# M3HM register map
File version: 0.1
Registers are 32-bit, read-write, reset 0x0 unless marked. A register's access mark holds for its fields unless they carry their own. Offsets are from the block's base; [hi:lo] are bit positions; {n}, {i} and the like mark numbered series.

## RPAR — RAM Parity
Base 0x400BBB00
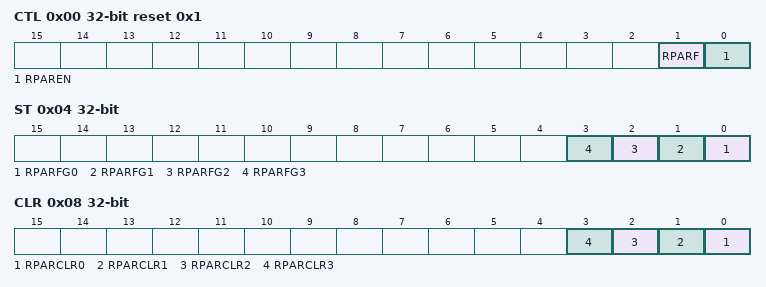
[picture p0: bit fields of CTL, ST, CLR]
0x00 CTL reset 0x1 — RAMM Parity control register
  [1] RPARF, [0] RPAREN
0x04 ST ro — RAMM Parity status register
  [n] RPARFG{n} (n=0..3)
0x08 CLR wo — RAMM Parity status clear register
  [n] RPARCLR{n} (n=0..3)
{0xC+4i} EAD{i} ro (i=0..3) — RAMM Parity Error address register {i}
  [31:0] RPAREADD{i}

## CRC
Base 0x400BBC00
0x00 DIN — CRC input data register
  [31:0] CRCDIN
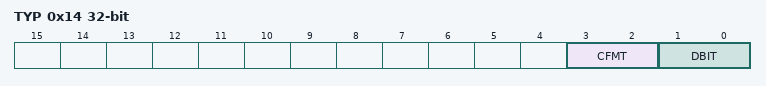
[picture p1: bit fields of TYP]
0x14 TYP — CRC data type register
  [3:2] CFMT, [1:0] DBIT
0x2C CLC reset 0xFFFFFFFF — CRC calculation result register
  [31:0] CRCCLC

## CMP
Base 0x400BC100
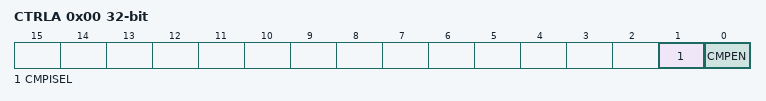
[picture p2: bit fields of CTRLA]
0x00 CTRLA — CMP control register A
  [1] CMPISEL, [0] CMPEN

## PA — Port A
Base 0x400C0000
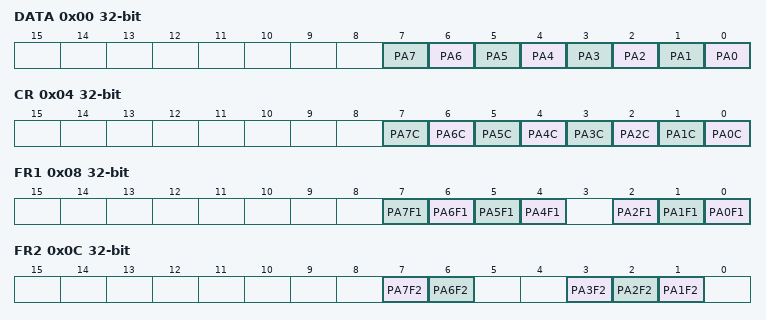
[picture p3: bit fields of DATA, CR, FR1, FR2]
0x00 DATA — PA Data Register
  [n] PA{n} (n=0..7)
0x04 CR — PA Control Register
  [n] PA{n}C (n=0..7)
0x08 FR1 — PA Function Register 1
  [n] PA{n}F1 (n=4..7), [2] PA2F1, [1] PA1F1, [0] PA0F1
0x0C FR2 — PA Function Register 2
  [7] PA7F2, [6] PA6F2, [3] PA3F2, [2] PA2F2, [1] PA1F2
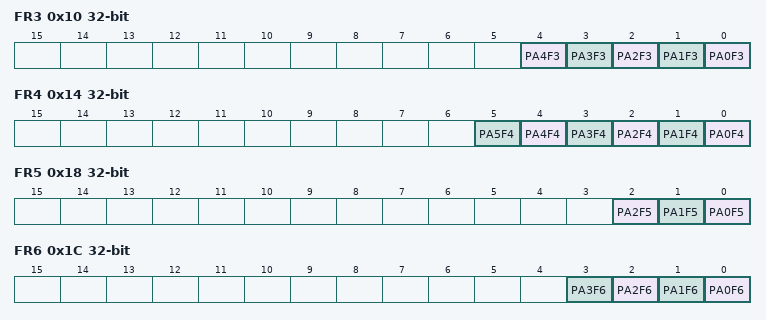
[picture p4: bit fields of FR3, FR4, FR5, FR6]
0x10 FR3 — PA Function Register 3
  [n] PA{n}F3 (n=0..4)
0x14 FR4 — PA Function Register 4
  [n] PA{n}F4 (n=0..5)
0x18 FR5 — PA Function Register 5
  [2] PA2F5, [1] PA1F5, [0] PA0F5
0x1C FR6 — PA Function Register 6
  [n] PA{n}F6 (n=0..3)
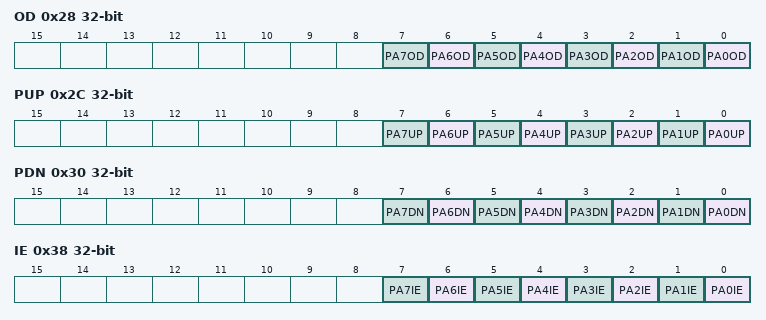
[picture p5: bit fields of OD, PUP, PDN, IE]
0x28 OD — PA Open Drain Control Register
  [n] PA{n}OD (n=0..7)
0x2C PUP — PA Pull-up Control Register
  [n] PA{n}UP (n=0..7)
0x30 PDN — PB Pull-Down Control Register
  [n] PA{n}DN (n=0..7)
0x38 IE — PA Input Enable Control Register
  [n] PA{n}IE (n=0..7)

## PB — Port B
Base 0x400C0100
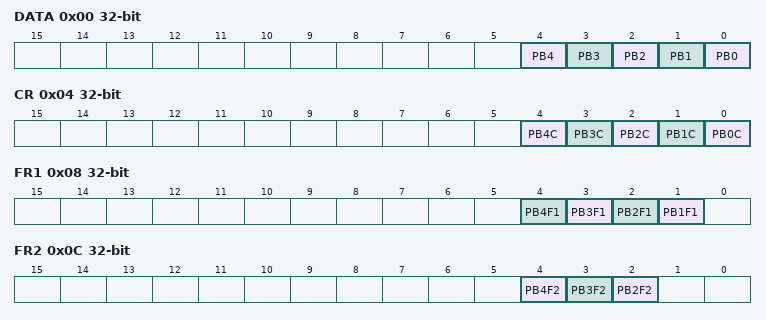
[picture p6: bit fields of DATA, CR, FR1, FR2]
0x00 DATA — PB Data Register
  [n] PB{n} (n=0..4)
0x04 CR — PB Control Register
  [n] PB{n}C (n=0..4)
0x08 FR1 — PB Function Register 1
  [n] PB{n}F1 (n=1..4)
0x0C FR2 — PB Function Register 2
  [4] PB4F2, [3] PB3F2, [2] PB2F2
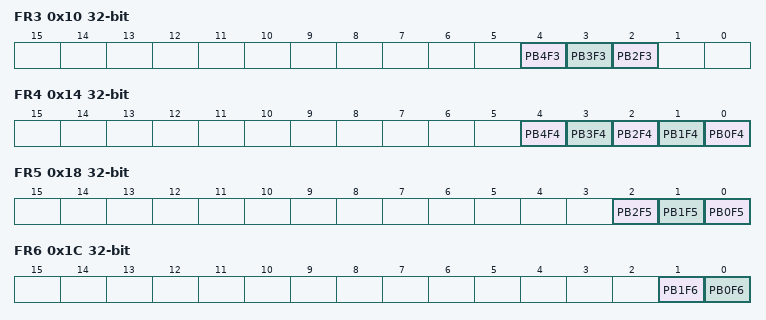
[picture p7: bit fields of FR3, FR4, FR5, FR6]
0x10 FR3 — PB Function Register 3
  [4] PB4F3, [3] PB3F3, [2] PB2F3
0x14 FR4 — PB Function Register 4
  [n] PB{n}F4 (n=0..4)
0x18 FR5 — PB Function Register 5
  [2] PB2F5, [1] PB1F5, [0] PB0F5
0x1C FR6 — PB Function Register 6
  [1] PB1F6, [0] PB0F6
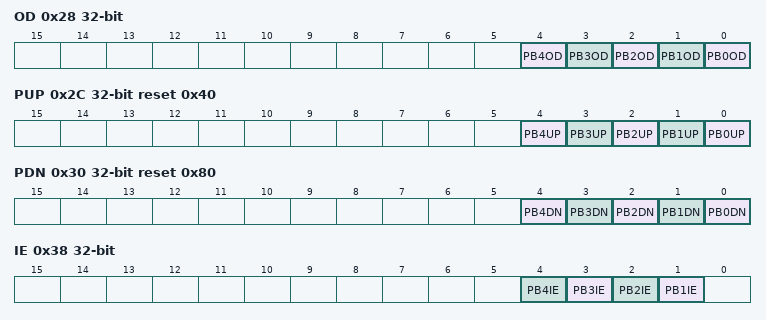
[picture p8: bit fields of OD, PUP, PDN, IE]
0x28 OD — PB Open Drain Control Register
  [n] PB{n}OD (n=0..4)
0x2C PUP reset 0x40 — PB Pull-up Control Register
  [n] PB{n}UP (n=0..4)
0x30 PDN reset 0x80 — PB Pull-Down Control Register
  [n] PB{n}DN (n=0..4)
0x38 IE — PB Input Enable Control Register
  [n] PB{n}IE (n=1..4)

## PC — Port C
Base 0x400C0200
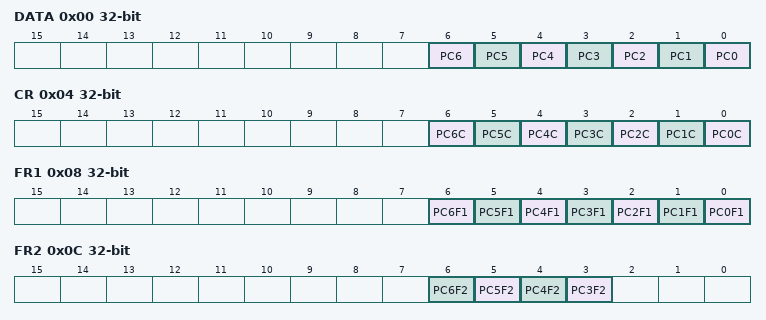
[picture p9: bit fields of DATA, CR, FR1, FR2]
0x00 DATA — PC Data Register
  [n] PC{n} (n=0..6)
0x04 CR — PC Control Register
  [n] PC{n}C (n=0..6)
0x08 FR1 — PC Function Register 1
  [n] PC{n}F1 (n=0..6)
0x0C FR2 — PC Function Register 2
  [n] PC{n}F2 (n=3..6)
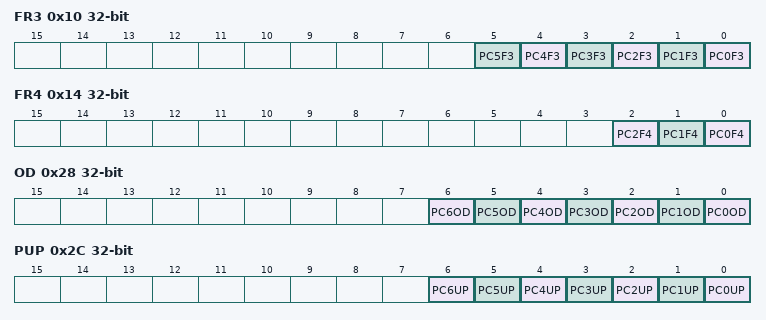
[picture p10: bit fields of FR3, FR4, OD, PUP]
0x10 FR3 — PC Function Register 3
  [n] PC{n}F3 (n=0..5)
0x14 FR4 — PC Function Register 4
  [2] PC2F4, [1] PC1F4, [0] PC0F4
0x18 FR5 — PC Function Register 5
  [2] PC2F5
0x28 OD — PC Open Drain Control Register
  [n] PC{n}OD (n=0..6)
0x2C PUP — PC Pull-up Control Register
  [n] PC{n}UP (n=0..6)
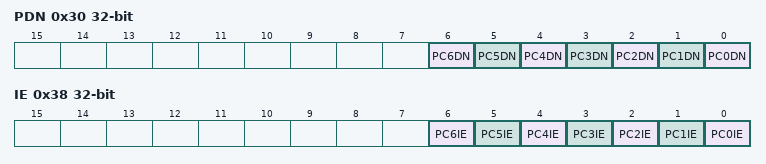
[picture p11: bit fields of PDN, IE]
0x30 PDN — PC Pull-Down Control Register
  [n] PC{n}DN (n=0..6)
0x38 IE — PC Input Enable Control Register
  [n] PC{n}IE (n=0..6)

## PD — Port D
Base 0x400C0300
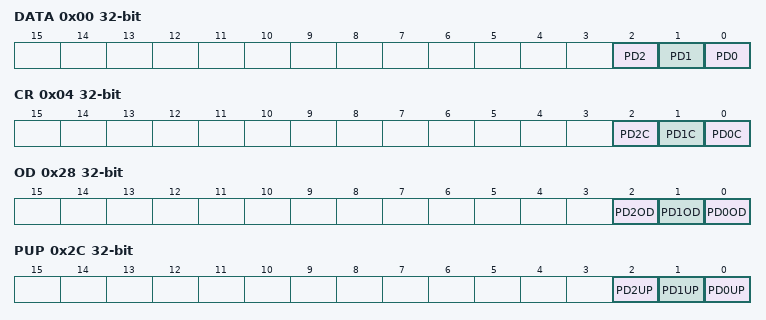
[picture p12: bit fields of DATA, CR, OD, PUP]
0x00 DATA — PD Data Register
  [2] PD2, [1] PD1, [0] PD0
0x04 CR — PD Control Register
  [2] PD2C, [1] PD1C, [0] PD0C
0x28 OD — PD Open Drain Control Register
  [2] PD2OD, [1] PD1OD, [0] PD0OD
0x2C PUP — PD Pull-up Control Register
  [2] PD2UP, [1] PD1UP, [0] PD0UP
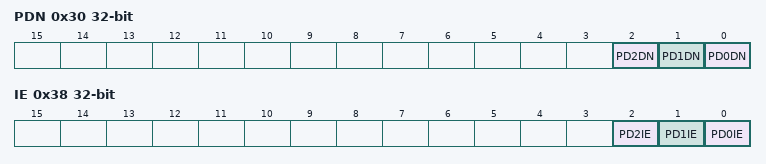
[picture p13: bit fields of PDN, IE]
0x30 PDN — PD Pull-Down Control Register
  [2] PD2DN, [1] PD1DN, [0] PD0DN
0x38 IE — PD Input Enable Control Register
  [2] PD2IE, [1] PD1IE, [0] PD0IE

## PE — Port E
Base 0x400C0400
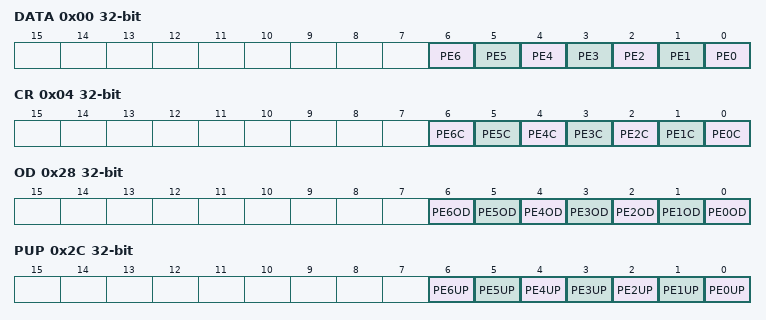
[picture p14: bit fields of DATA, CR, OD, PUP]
0x00 DATA — PE Data Register
  [n] PE{n} (n=0..6)
0x04 CR — PE Control Register
  [n] PE{n}C (n=0..6)
0x28 OD — PE Open Drain Control Register
  [n] PE{n}OD (n=0..6)
0x2C PUP — PE Pull-up Control Register
  [n] PE{n}UP (n=0..6)
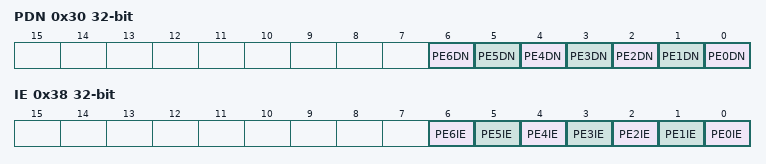
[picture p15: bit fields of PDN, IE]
0x30 PDN — PE Pull-Down Control Register
  [n] PE{n}DN (n=0..6)
0x38 IE — PE Input Enable Control Register
  [n] PE{n}IE (n=0..6)
